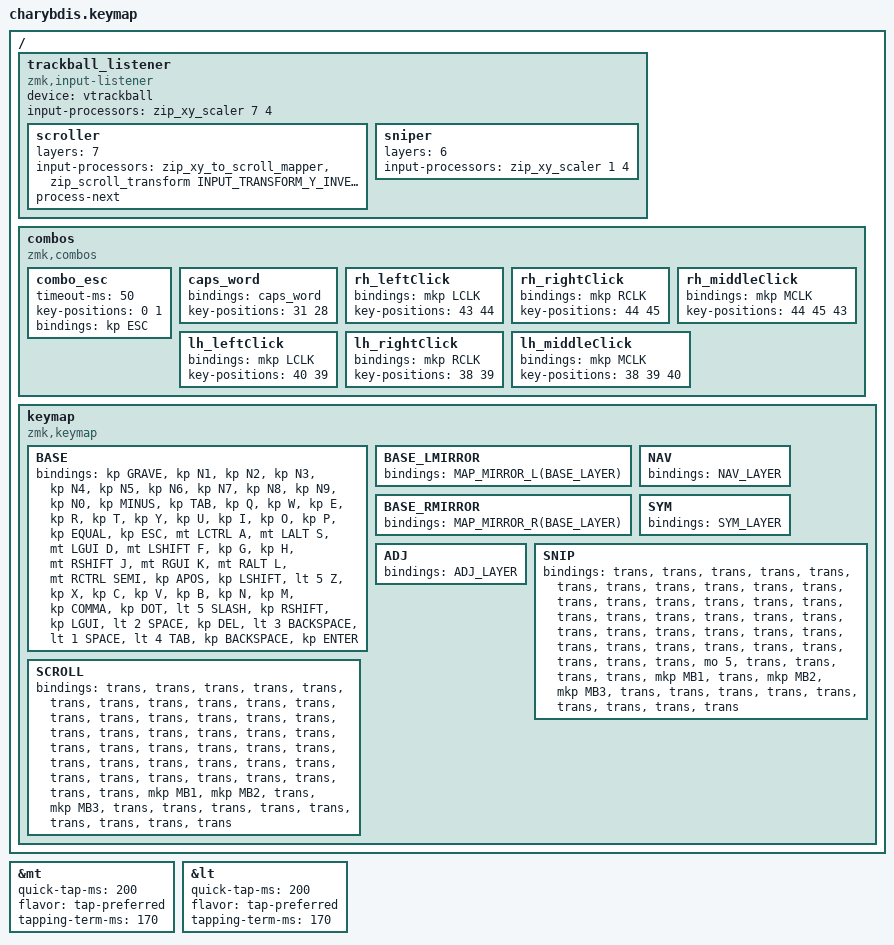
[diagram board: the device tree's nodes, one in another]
#include <dt-bindings/zmk/mouse.h>
#include <behaviors/mouse_keys.dtsi>
#include <behaviors.dtsi>
#include <dt-bindings/zmk/bt.h>
#include <dt-bindings/zmk/ext_power.h>
#include <dt-bindings/zmk/keys.h>
#include <dt-bindings/zmk/outputs.h>
#include <dt-bindings/zmk/pointing.h>
#include <dt-bindings/zmk/input_transform.h>
#include <input/processors.dtsi>
#include "layer_reorder.h"

/ {
    // chosen { zmk,matrix_transform = &default_transform; };

    /* input config for mouse move mode */

    trackball_listener {
        compatible = "zmk,input-listener";
        device = <&vtrackball>;
        input-processors = <&zip_xy_scaler 7 4>;
        scroller {
            layers = <7>;
            input-processors = <&zip_xy_to_scroll_mapper>, <&zip_scroll_transform INPUT_TRANSFORM_Y_INVERT>;
            process-next;
        };
        sniper {
            layers = <6>;
            input-processors = <&zip_xy_scaler 1 4>;
        };
    };
};

&mt {
    quick-tap-ms = <200>;
    flavor = "tap-preferred";
    tapping-term-ms = <170>;
};

&lt {
    quick-tap-ms = <200>;
    flavor = "tap-preferred";
    tapping-term-ms = <170>;
};

/ {
    combos {
        compatible = "zmk,combos";

        combo_esc {
            timeout-ms = <50>;
            key-positions = <0 1>;
            bindings = <&kp ESC>;
        };

        caps_word {
            bindings = <&caps_word>;
            key-positions = <31 28>;
        };

        rh_leftClick {
            bindings = <&mkp LCLK>;
            key-positions = <43 44>;
        };

        rh_rightClick {
            bindings = <&mkp RCLK>;
            key-positions = <44 45>;
        };

        rh_middleClick {
            bindings = <&mkp MCLK>;
            key-positions = <44 45 43>;
        };

        lh_leftClick {
            bindings = <&mkp LCLK>;
            key-positions = <40 39>;
        };

        lh_rightClick {
            bindings = <&mkp RCLK>;
            key-positions = <38 39>;
        };

        lh_middleClick {
            bindings = <&mkp MCLK>;
            key-positions = <38 39 40>;
        };
    };

#define MAP_MIRROR(l) \
        _G(11,l) _G(10,l) _G(9,l)  _G(8,l)  _G(7,l)  _G(6,l)   _G(5,l)  _G(4,l)  _G(3,l)  _G(2,l)  _G(1,l)  _G(0,l) \
        _G(23,l) _G(22,l) _G(21,l) _G(20,l) _G(19,l) _G(18,l)  _G(17,l) _G(16,l) _G(15,l) _G(14,l) _G(13,l) _G(12,l) \
        _G(35,l) _G(34,l) _G(33,l) _G(32,l) _G(31,l) _G(30,l)  _G(29,l) _G(28,l) _G(27,l) _G(26,l) _G(25,l) _G(24,l) \
        _G(47,l) _G(46,l) _G(45,l) _G(44,l) _G(43,l) _G(42,l)  _G(41,l) _G(40,l) _G(39,l) _G(38,l) _G(37,l) _G(36,l) \
                                _G(48,l) _G(52,l) _G(51,l)  _G(50,l) _G(49,l) \
                                        _G(55,l) _G(54,l)  _G(53,l)

#define MAP_MIRROR_L(l) \
        &trans &trans &trans &trans &trans &trans   _G(5,l)  _G(4,l)  _G(3,l)  _G(2,l)  _G(1,l)  _G(0,l) \
        &trans &trans &trans &trans &trans &trans   _G(17,l) _G(16,l) _G(15,l) _G(14,l) _G(13,l) _G(12,l) \
        &trans &trans &trans &trans &trans &trans   _G(29,l) _G(28,l) _G(27,l) _G(26,l) _G(25,l) _G(24,l) \
        &trans &trans &trans &trans &trans &trans   _G(41,l) _G(40,l) _G(39,l) _G(38,l) _G(37,l) _G(36,l) \
                             &trans &trans &trans   _G(50,l) _G(49,l) \
                                    &trans &trans   _G(53,l)

#define MAP_MIRROR_R(l) \
        _G(11,l) _G(10,l) _G(9,l)  _G(8,l)  _G(7,l)  _G(6,l)   &trans &trans &trans &trans &trans &trans \
        _G(23,l) _G(22,l) _G(21,l) _G(20,l) _G(19,l) _G(18,l)  &trans &trans &trans &trans &trans &trans \
        _G(35,l) _G(34,l) _G(33,l) _G(32,l) _G(31,l) _G(30,l)  &trans &trans &trans &trans &trans &trans \
        _G(47,l) _G(46,l) _G(45,l) _G(44,l) _G(43,l) _G(42,l)  &trans &trans &trans &trans &trans &trans \
                                _G(48,l) _G(52,l) _G(51,l)  &trans &trans \
                                        _G(55,l) _G(54,l)  &trans


    keymap {
        compatible = "zmk,keymap";

        BASE {
#define BASE_LAYER \
    (&kp GRAVE)   (&kp N1)       (&kp N2)      (&kp N3)      (&kp N4)        (&kp N5)           (&kp N6)           (&kp N7)        (&kp N8)      (&kp N9)      (&kp N0)          (&kp MINUS) \
    (&kp TAB)     (&kp Q)        (&kp W)       (&kp E)       (&kp R)         (&kp T)            (&kp Y)            (&kp U)         (&kp I)       (&kp O)       (&kp P)           (&kp EQUAL) \
    (&kp ESC)     (&mt LCTRL A)  (&mt LALT S)  (&mt LGUI D)  (&mt LSHIFT F)  (&kp G)            (&kp H)            (&mt RSHIFT J)  (&mt RGUI K)  (&mt RALT L)  (&mt RCTRL SEMI)  (&kp APOS) \
    (&kp LSHIFT)  (&lt 5 Z)      (&kp X)       (&kp C)       (&kp V)         (&kp B)            (&kp N)            (&kp M)         (&kp COMMA)   (&kp DOT)     (&lt 5 SLASH)     (&kp RSHIFT) \
                                               (&kp LGUI)    (&lt 2 SPACE)   (&kp DEL)          (&lt 3 BACKSPACE)  (&lt 1 SPACE) \
                                                             (&lt 4 TAB)     (&kp BACKSPACE)    (&kp ENTER)
            bindings = <
    &kp GRAVE   &kp N1       &kp N2      &kp N3      &kp N4        &kp N5           &kp N6           &kp N7        &kp N8      &kp N9      &kp N0          &kp MINUS
    &kp TAB     &kp Q        &kp W       &kp E       &kp R         &kp T            &kp Y            &kp U         &kp I       &kp O       &kp P           &kp EQUAL
    &kp ESC     &mt LCTRL A  &mt LALT S  &mt LGUI D  &mt LSHIFT F  &kp G            &kp H            &mt RSHIFT J  &mt RGUI K  &mt RALT L  &mt RCTRL SEMI  &kp APOS
    &kp LSHIFT  &lt 5 Z      &kp X       &kp C       &kp V         &kp B            &kp N            &kp M         &kp COMMA   &kp DOT     &lt 5 SLASH     &kp RSHIFT
                                               &kp LGUI    &lt 2 SPACE   &kp DEL          &lt 3 BACKSPACE  &lt 1 SPACE
                                                             &lt 4 TAB     &kp BACKSPACE    &kp ENTER
            >;
        };
        BASE_LMIRROR {
            bindings = < MAP_MIRROR_L(BASE_LAYER) >;
        };
        BASE_RMIRROR {
            bindings = < MAP_MIRROR_R(BASE_LAYER) >;
        };

        NAV {
#define NAV_LAYER \
&kp F12        &kp F1           &kp F2     &kp F3     &kp F4           &kp F5               &kp F6      &kp F7          &kp F8           &kp F9      &kp F10    &kp F11 \
&kp KP_NUM     &kp KP_PLUS      &kp KP_N7  &kp KP_N8  &kp KP_N9        &kp LBRC             &kp RBRC    &kp SCROLLLOCK  &kp PAUSE_BREAK  &kp INSERT  &kp EQUAL  &trans \
&kp KP_DIVIDE  &kp KP_MINUS     &kp KP_N4  &kp KP_N5  &kp KP_N6        &kp LBKT             &kp RBKT    &kp LEFT        &kp DOWN         &kp UP      &kp RIGHT  &kp PRINTSCREEN \
&trans         &kp KP_MULTIPLY  &kp KP_N1  &kp KP_N2  &kp KP_N3        &kp LPAR             &kp RPAR    &kp DEL         &kp PG_UP        &kp CAPS    &kp PG_DN  &trans \
                                                 &kp KP_N0  &kp C_VOLUME_UP  &kp C_VOLUME_DOWN    &mo 5       &trans \
                                                              &trans           &trans               &kp KP_DOT
            bindings = <NAV_LAYER>;
        };

        SYM {
#define SYM_LAYER \
&kp F12  &kp F1         &kp F2     &kp F3             &kp F4            &kp F5           &kp F6              &kp F7            &kp F8     &kp F9        &kp F10        &kp F11 \
&trans   &kp EXCL       &kp AT     &kp HASH           &kp DLLR          &kp PRCNT        &kp CARET           &kp AMPS          &kp STAR   &kp QUESTION  &kp SQT        &trans \
&trans   &kp PLUS       &kp EQUAL  &kp LPAR           &kp RPAR          &kp DQT          &kp COLON           &kp LBKT          &kp RBKT   &kp LBRC      &kp RBRC       &trans \
&trans   &kp LESS_THAN  &kp PIPE   &kp MINUS          &kp GREATER_THAN  &kp BACKSLASH    &kp GRAVE           &kp UNDERSCORE    &kp SLASH  &kp TILDE     &kp SEMICOLON  &trans \
                                         &kp C_VOLUME_DOWN  &kp C_VOLUME_UP   &trans           &trans              &kp C_PLAY_PAUSE \
                                                              &mo 5             &trans           &kt C_FAST_FORWARD
            bindings = <SYM_LAYER>;
        };

        ADJ {
#define ADJ_LAYER \
&kp F12  &kp F1             &kp F2          &kp F3            &kp F4             &kp F5             &kp F6        &kp F7      &kp F8      &kp F9             &kp F10      &kp F11 \
&trans   &sys_reset         &bt BT_PRV      &bt BT_NXT        &bt BT_CLR         &out OUT_TOG       &bt BT_SEL 0  &bt BT_CLR  &bt BT_PRV  &bt BT_NXT         &sys_reset   &trans \
&trans   &bootloader        &kp C_PREVIOUS  &kp C_PLAY_PAUSE  &kp C_NEXT         &kp C_MUTE         &bt BT_SEL 1  &trans      &trans      &ext_power EP_TOG  &bootloader  &trans \
&trans   &ext_power EP_TOG  &mo 5           &mo 4             &kp C_VOLUME_DOWN  &kp C_VOLUME_UP    &bt BT_SEL 2  &trans      &mo 6       &mo 7              &trans       &trans \
                                                  &trans            &trans             &trans             &trans        &trans \
                                                                      &trans             &trans             &trans
            bindings = <ADJ_LAYER>;
        };

        SNIP {
            bindings = <
&trans  &trans  &trans  &trans  &trans  &trans    &trans  &trans    &trans    &trans    &trans    &trans
&trans  &trans  &trans  &trans  &trans  &trans    &trans  &trans    &trans    &trans    &trans    &trans
&trans  &trans  &trans  &trans  &trans  &trans    &trans  &trans    &trans    &trans    &trans    &trans
&trans  &trans  &mo 5   &trans  &trans  &trans    &trans  &mkp MB1  &trans    &mkp MB2  &mkp MB3  &trans
                        &trans  &trans  &trans    &trans  &trans
                                &trans  &trans    &trans
            >;
        };

        SCROLL {
            bindings = <
&trans  &trans  &trans  &trans  &trans  &trans    &trans  &trans    &trans    &trans    &trans    &trans
&trans  &trans  &trans  &trans  &trans  &trans    &trans  &trans    &trans    &trans    &trans    &trans
&trans  &trans  &trans  &trans  &trans  &trans    &trans  &trans    &trans    &trans    &trans    &trans
&trans  &trans  &trans  &trans  &trans  &trans    &trans  &mkp MB1  &mkp MB2  &trans    &mkp MB3  &trans
                        &trans  &trans  &trans    &trans  &trans
                                &trans  &trans    &trans
            >;
        };
    };
};
